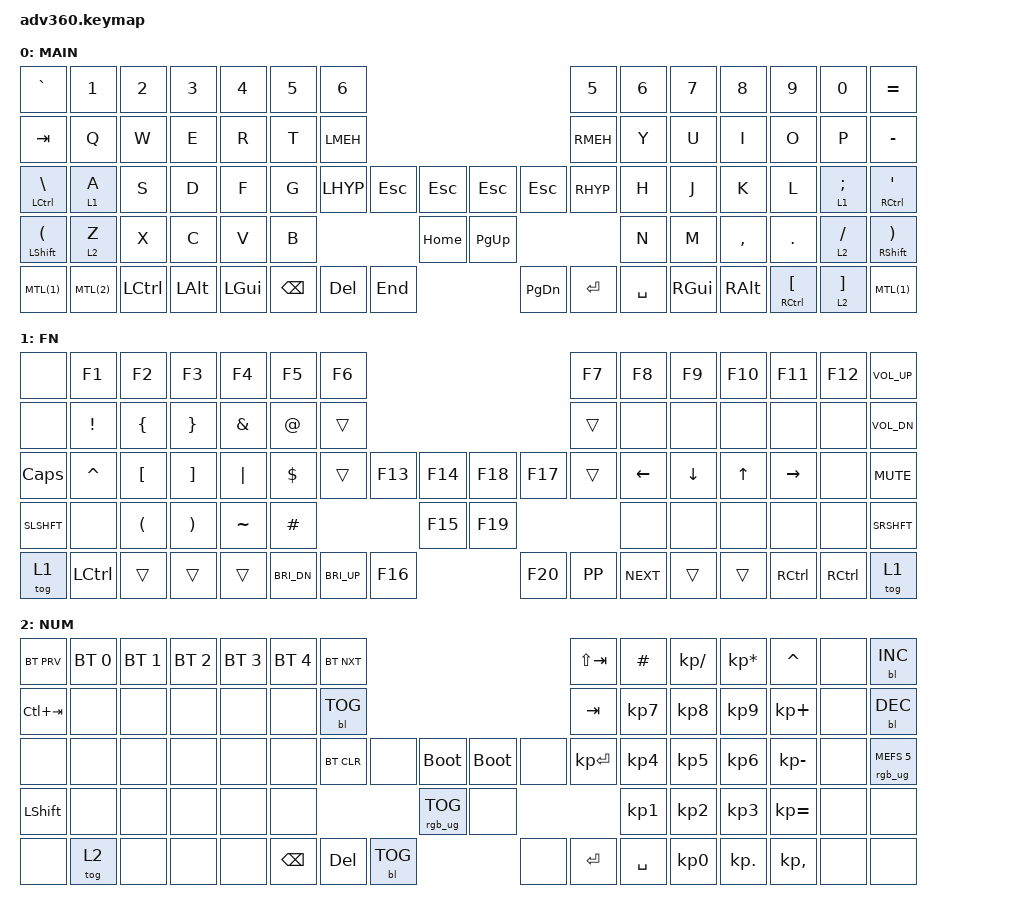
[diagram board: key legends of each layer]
#include <behaviors.dtsi>
#include <dt-bindings/zmk/keys.h>
#include <dt-bindings/zmk/bt.h>
#include <dt-bindings/zmk/rgb.h>
#include <dt-bindings/zmk/backlight.h>

#define MTL(layer) &mo_tog layer layer   // Macro to apply momentary-layer-on-hold/toggle-layer-on-tap to a specific layer
#define LMEH       LS(LA(LCTRL))         // Macro defining the Left `Meh` (Shift + Alt + Control) key
#define RMEH       RS(RA(RCTRL))         // Macro defining the Right `Meh` (Shift + Alt + Control) key
#define LHYP       LS(LA(LC(LGUI)))      // Macro defining the Left `Hyper` (Shift + Alt + Control + Command) key
#define RHYP       RS(RA(RC(RGUI)))      // Macro defining the Right `Hyper` (Shift + Alt + Control + Command) key

/ {
  behaviors {
    #include "macros.dtsi"

    mo_tog: behavior_mo_tog {
      compatible = "zmk,behavior-hold-tap";
      label = "mo_tog";
      #binding-cells = <2>;
      tapping-term-ms = <200>;
      quick_tap_ms = <175>;
      flavor = "hold-preferred";
      bindings = <&mo>, <&tog>;
    };

    hm: homerow_mods {
        compatible = "zmk,behavior-hold-tap";
        label = "HOMEROW_MODS";
        #binding-cells = <2>;
        tapping-term-ms = <200>;
        quick_tap_ms = <175>;
        flavor = "tap-preferred";
        bindings = <&kp>, <&kp>;
    };

    hl: homerow_layer {
      compatible = "zmk,behavior-hold-tap";
      label = "HOMEROW_LAYERS";
      #binding-cells = <2>;
      tapping-term-ms = <200>;
      quick_tap_ms = <175>;
      flavor = "tap-preferred";
      bindings = <&mo>, <&kp>;
    };

    CPSWL: caps_word_lock {
      compatible = "zmk,behavior-caps-word";
      label = "CAPS_WORD";
      #binding-cells = <0>;
      continue-list = <UNDERSCORE MINUS>;
    };

    SLSHFT: left_sticky_shift {
      compatible = "zmk,behavior-tap-dance";
      label = "sticky_shift";
      #binding-cells = <0>;
      bindings = <&CPSWL>, <&kp LSHFT>;
    };

    SRSHFT: right_sticky_shift {
      compatible = "zmk,behavior-tap-dance";
      label = "sticky_shift";
      #binding-cells = <0>;
      bindings = <&CPSWL>, <&kp RSHFT>;
    };
  };

  /*
   * Keyboard layout:
   * +-------------------------+-------------+-------------+-------------------------+
   * |  [ ][ ][ ][ ][ ][ ][ ]  |             |             |  [ ][ ][ ][ ][ ][ ][ ]  |
   * |  [ ][ ][ ][ ][ ][ ][ ]  |             |             |  [ ][ ][ ][ ][ ][ ][ ]  |
   * |  [ ][ ][ ][ ][ ][ ][ ]  |     [ ][ ]  |  [ ][ ]     |  [ ][ ][ ][ ][ ][ ][ ]  |
   * |  [ ][ ][ ][ ][ ][ ]     |        [ ]  |  [ ]        |     [ ][ ][ ][ ][ ][ ]  |
   * |  [ ][ ][ ][ ][ ]        |  [ ][ ][ ]  |  [ ][ ][ ]  |        [ ][ ][ ][ ][ ]  |
   * +-------------------------+-------------+-------------+-------------------------+
   *     ↑                         ↑             ↑                   ↑
   *     |                         |             |                   |
   *     |                         |             |                   +--- Right side main cluster
   *     |                         |             +--- Right side thumb cluster
   *     |                         +--- Left side thumb cluster
   *     +--- Left side main cluster
   *
   *
   *            * * * * * * * * * * * * * * * * * * * * * * * * * * * * * * * * * * *
   *            * MAKE SURE YOU DISABLE WORD-WRAP ON YOUR EDITOR TO EDIT THIS FILE! *
   *            * * * * * * * * * * * * * * * * * * * * * * * * * * * * * * * * * * *
   */

  keymap {
    compatible = "zmk,keymap";

    MAIN {
      bindings = <
        &kp GRAVE       &kp N1    &kp N2     &kp N3    &kp N4     &kp N5  &kp N6                                                                     &kp N5    &kp N6  &kp N7    &kp N8     &kp N9          &kp N0      &kp EQUAL
        &kp TAB         &kp Q     &kp W      &kp E     &kp R      &kp T   &kp LMEH                                                                   &kp RMEH  &kp Y   &kp U     &kp I      &kp O           &kp P       &kp MINUS
        &mt LCTRL BSLH  &hl 1 A   &kp S      &kp D     &kp F      &kp G   &kp LHYP            &kp ESC    &kp ESC    &kp ESC    &kp ESC               &kp RHYP  &kp H   &kp J     &kp K      &kp L           &hl 1 SEMI  &mt RCTRL SQT
        &mt LSHFT LPAR  &hl 2 Z   &kp X      &kp C     &kp V      &kp B                                  &kp HOME   &kp PG_UP                                  &kp N   &kp M     &kp COMMA  &kp DOT         &hl 2 FSLH  &mt RSHFT RPAR
        MTL(1)          MTL(2)    &kp LCTRL  &kp LALT  &kp LGUI                     &kp BSPC  &kp DEL    &kp END    &kp PG_DN  &kp ENTER  &kp SPACE                    &kp RGUI  &kp RALT   &mt RCTRL LBKT  &hl 2 RBKT  MTL(1)
      >;
    };
    FN {
      bindings = <
        &none     &kp F1     &kp F2    &kp F3    &kp F4     &kp F5    &kp F6                                                                        &kp F7  &kp F8    &kp F9    &kp F10  &kp F11    &kp F12    &kp C_VOL_UP
        &none     &kp EXCL   &kp LBRC  &kp RBRC  &kp AMPS   &kp AT    &trans                                                                        &trans  &none     &none     &none    &none      &none      &kp C_VOL_DN
        &kp CAPS  &kp CARET  &kp LBKT  &kp RBKT  &kp PIPE   &kp DLLR  &trans                &kp F13       &kp F14   &kp F18  &kp F17                &trans  &kp LEFT  &kp DOWN  &kp UP   &kp RIGHT  &none      &kp K_MUTE
        &SLSHFT   &none      &kp LPAR  &kp RPAR  &kp TILDE  &kp HASH                                      &kp F15   &kp F19                                 &none     &none     &none    &none      &none      &SRSHFT
        &tog 1    &kp LCTRL  &trans    &trans    &trans                       &kp C_BRI_DN  &kp C_BRI_UP  &kp F16   &kp F20  &kp K_PP   &kp K_NEXT                    &trans    &trans   &kp RCTRL  &kp RCTRL  &tog 1
      >;
    };
    NUM {
      bindings = <
        &bt BT_PRV   &bt BT_SEL 0  &bt BT_SEL 1  &bt BT_SEL 2  &bt BT_SEL 3  &bt BT_SEL 4  &bt BT_NXT                                                                        &kp LS(TAB)   &kp HASH   &kp KP_DIVIDE  &kp KP_MULTIPLY  &kp CARET     &none  &bl BL_INC
        &kp LC(TAB)  &none         &none         &none         &none         &none         &bl BL_TOG                                                                        &kp TAB       &kp KP_N7  &kp KP_N8      &kp KP_N9        &kp KP_PLUS   &none  &bl BL_DEC
        &none        &none         &none         &none         &none         &none         &bt BT_CLR            &none    &bootloader       &bootloader  &none               &kp KP_ENTER  &kp KP_N4  &kp KP_N5      &kp KP_N6        &kp KP_MINUS  &none  &rgb_ug RGB_MEFS_CMD 5
        &kp LSHFT    &none         &none         &none         &none         &none                                        &rgb_ug RGB_TOG   &none                                          &kp KP_N1  &kp KP_N2      &kp KP_N3        &kp KP_EQUAL  &none  &none
        &none        &tog 2        &none         &none         &none                                   &kp BSPC  &kp DEL  &bl BL_TOG        &none        &kp RET  &kp SPACE                           &kp KP_N0      &kp KP_DOT       &kp KP_COMMA  &none  &none
      >;
    };
  };
};
